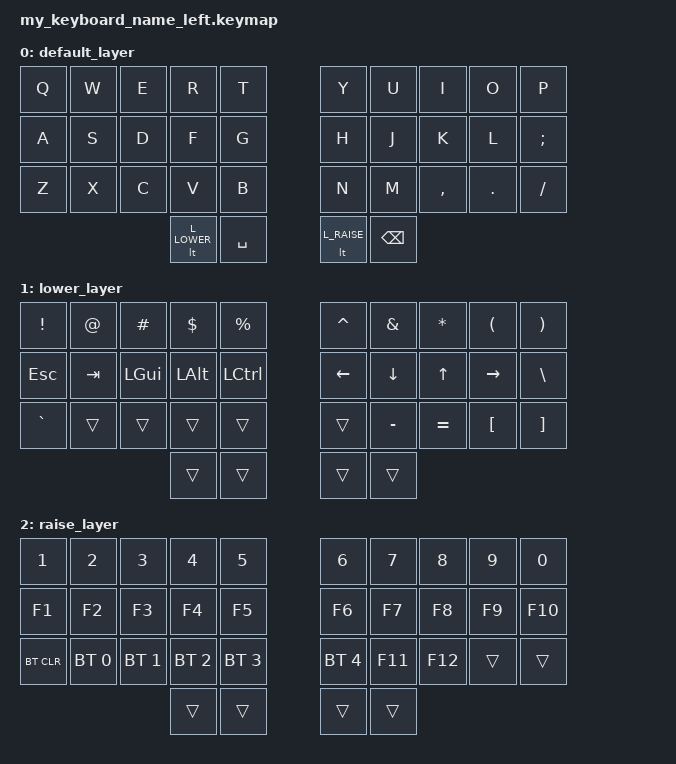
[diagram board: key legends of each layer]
// my_keyboard_name.keymap

#include <behaviors.dtsi>
#include <dt-bindings/zmk/keys.h>
#include <dt-bindings/zmk/bt.h>

#define L_LOWER 0
#define L_RAISE 1

/ {
    keymap {
        compatible = "zmk,keymap";

        default_layer {
            bindings = <
            // ---------------------------------------------------------------------------------
            // | 左手側                                   | 右手側                                   |
            // ---------------------------------------------------------------------------------
            &kp Q      &kp W      &kp E      &kp R      &kp T         &kp Y      &kp U      &kp I      &kp O      &kp P
            &kp A      &kp S      &kp D      &kp F      &kp G         &kp H      &kp J      &kp K      &kp L      &kp SEMI
            &kp Z      &kp X      &kp C      &kp V      &kp B         &kp N      &kp M      &kp COMMA  &kp DOT    &kp FSLH
                                  &lt L_LOWER &kp SPC       &lt L_RAISE &kp BSPC
            >;
        };

        lower_layer {
            bindings = <
            // ---------------------------------------------------------------------------------
            // | 左手側                                   | 右手側                                   |
            // ---------------------------------------------------------------------------------
            &kp EXCL   &kp AT     &kp HASH   &kp DLLR   &kp PRCNT       &kp CARET  &kp AMPS   &kp ASTRK  &kp LPAR   &kp RPAR
            &kp ESC    &kp TAB    &kp LGUI   &kp LALT   &kp LCTRL       &kp LEFT   &kp DOWN   &kp UP     &kp RIGHT  &kp BSLH
            &kp GRAVE  &trans     &trans     &trans     &trans        &trans     &kp MINUS  &kp EQUAL  &kp LBKT   &kp RBKT
                                  &trans     &trans        &trans     &trans
            >;
        };

        raise_layer {
            bindings = <
            // ---------------------------------------------------------------------------------
            // | 左手側                                   | 右手側                                   |
            // ---------------------------------------------------------------------------------
            &kp N1     &kp N2     &kp N3     &kp N4     &kp N5          &kp N6     &kp N7     &kp N8     &kp N9     &kp N0
            &kp F1     &kp F2     &kp F3     &kp F4     &kp F5          &kp F6     &kp F7     &kp F8     &kp F9     &kp F10
            &bt BT_CLR &bt BT_SEL 0 &bt BT_SEL 1 &bt BT_SEL 2 &bt BT_SEL 3 &bt BT_SEL 4  &kp F11    &kp F12    &trans     &trans
                                  &trans     &trans        &trans     &trans
            >;
        };
    };
};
